# STM32L0x0 register map
File version: 1.3
CPU: CM0+ r0p0, little endian, MPU, no FPU, 2 interrupt priority bits
Registers are 32-bit, read-write, reset 0x0 unless marked. A register's access mark holds for its fields unless they carry their own. Offsets are from the block's base; [hi:lo] are bit positions; {n}, {i} and the like mark numbered series; 'fields as' and 'values as' point back to an identical list.

## IWDG — Independent watchdog
Base 0x40003000
0x00 KR 16-bit wo — Key register
  [15:0] KEY — Key value (write only, read 0x0000)
    0x5555=Unlock (Enable access to PR, RLR and WINR registers); 0xAAAA=Feed watchdog with RLR register value; 0xCCCC=Start the watchdog
0x04 PR 16-bit — Prescaler register
  [2:0] PR — Prescaler divider
    0=DivideBy4 (Divider /4); 1=DivideBy8 (Divider /8); 2=DivideBy16 (Divider /16); 3=DivideBy32 (Divider /32); 4=DivideBy64 (Divider /64); 5=DivideBy128 (Divider /128); other=DivideBy256 (Divider /256)
0x08 RLR 16-bit reset 0xFFF — Reload register
  [11:0] RL — Watchdog counter reload value
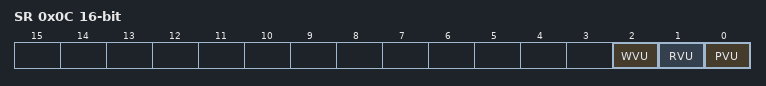
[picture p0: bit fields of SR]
0x0C SR 16-bit ro — Status register
  [2] WVU — Watchdog counter window value update
  [1] RVU — Watchdog counter reload value update
  [0] PVU — Watchdog prescaler value update
0x10 WINR 16-bit reset 0xFFF — Window register
  [11:0] WIN — Watchdog counter window value

## WWDG — System window watchdog
Base 0x40002C00
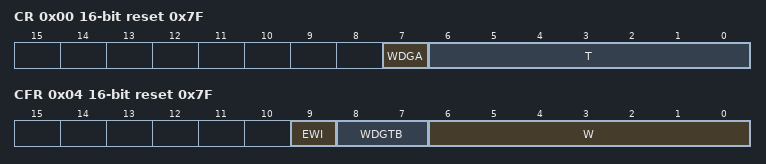
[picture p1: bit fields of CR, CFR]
0x00 CR 16-bit reset 0x7F — Control register
  [7] WDGA — Activation bit
    0=Disabled (Watchdog disabled); 1=Enabled (Watchdog enabled)
  [6:0] T — 7-bit counter (MSB to LSB)
0x04 CFR 16-bit reset 0x7F — Configuration register
  [9] EWI — Early wakeup interrupt
    on write: 1=Enable (interrupt occurs whenever the counter reaches the value 0x40)
  [8:7] WDGTB — Timer base
    0=Div1 (Counter clock (PCLK1 div 4096) div 1); 1=Div2 (Counter clock (PCLK1 div 4096) div 2); 2=Div4 (Counter clock (PCLK1 div 4096) div 4); 3=Div8 (Counter clock (PCLK1 div 4096) div 8)
  [6:0] W — 7-bit window value
0x08 SR 16-bit — Status register
  [0] EWIF write-0-clears — Early wakeup interrupt flag
    on read: 0=Finished (The EWI Interrupt Service Routine has been serviced); 1=Pending (The EWI Interrupt Service Routine has been triggered) | on write: 0=Finished (The EWI Interrupt Service Routine has been serviced)

## FW — Firewall
Base 0x40011C00
0x00 CSSA — Code segment start address
  [23:8] ADD — code segment start address
0x04 CSL — Code segment length
  [21:8] LENG — code segment length
0x08 NVDSSA — Non-volatile data segment start address
  [23:8] ADD
0x0C NVDSL — Non-volatile data segment length
  [21:8] LENG
0x10 VDSSA — Volatile data segment start address
  [15:6] ADD
0x14 VDSL — Volatile data segment length
  [15:6] LENG — Non-volatile data segment length
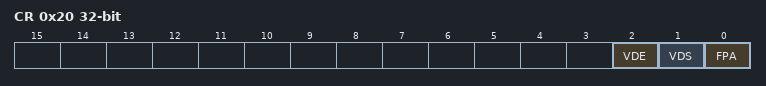
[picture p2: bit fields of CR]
0x20 CR — Configuration register
  [2] VDE — Volatile data execution
    on read: 0=NotExecutable (Volatile data segment cannot be executed if VDS = 0); 1=Executable (Volatile data segment is declared executable whatever VDS bit value) | on write: 0=Resets volatile data execution bit
  [1] VDS — Volatile data shared
    on read: 0=NotShared (Volatile data segment is not shared and cannot be hit by a non protected executable code when the Firewall is closed); 1=Shared (Volatile data segment is shared with non protected application code) | on write: 0=Resets volatile data shared bit
  [0] FPA — Firewall pre alarm
    on write: 0=PreArmReset (Any code executed outside the protected segment when the Firewall is opened will generate a system reset); 1=PreArmSet (Any code executed outside the protected segment will close the Firewall)

## EXTI — External interrupt/event controller
Base 0x40010400
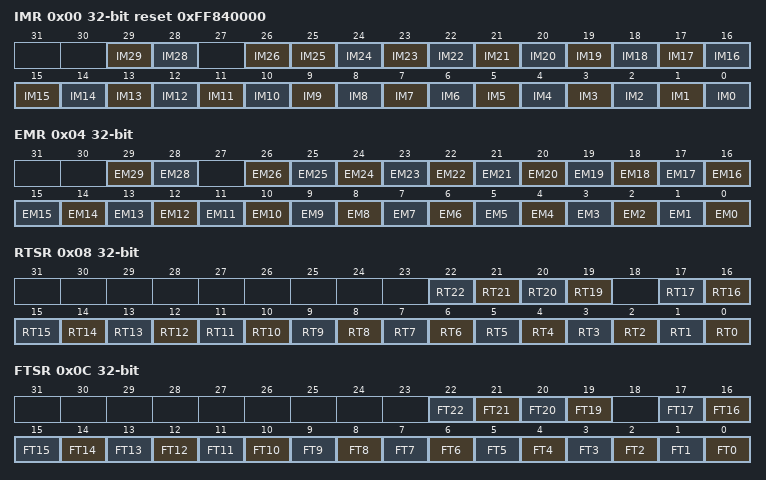
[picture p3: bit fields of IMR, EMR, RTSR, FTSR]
0x00 IMR reset 0xFF840000 — Interrupt mask register (EXTI_IMR)
  [all] fields
    0=Masked (Interrupt request line is masked); 1=Unmasked (Interrupt request line is unmasked)
  [29] IM29 — Interrupt Mask on line 27
  [28] IM28 — Interrupt Mask on line 27
  [26] IM26 — Interrupt Mask on line 27
  [n] IM{n} (n=0..25) — Interrupt Mask on line {n}
0x04 EMR — Event mask register (EXTI_EMR)
  [all] fields
    0=Masked (Event request line is masked); 1=Unmasked (Event request line is unmasked)
  [29] EM29 — Event Mask on line 29
  [28] EM28 — Event Mask on line 28
  [n] EM{n} (n=0..26) — Event Mask on line {n}
0x08 RTSR — Rising Trigger selection register (EXTI_RTSR)
  [all] fields
    0=Disabled (Rising edge trigger is disabled); 1=Enabled (Rising edge trigger is enabled)
  [n] RT{n} (n=19..22) — Rising trigger event configuration of line {n}
  [n] RT{n} (n=0..17) — Rising trigger event configuration of line {n}
0x0C FTSR — Falling Trigger selection register (EXTI_FTSR)
  [all] fields
    0=Disabled (Falling edge trigger is disabled); 1=Enabled (Falling edge trigger is enabled)
  [n] FT{n} (n=19..22) — Falling trigger event configuration of line {n}
  [n] FT{n} (n=0..17) — Falling trigger event configuration of line {n}
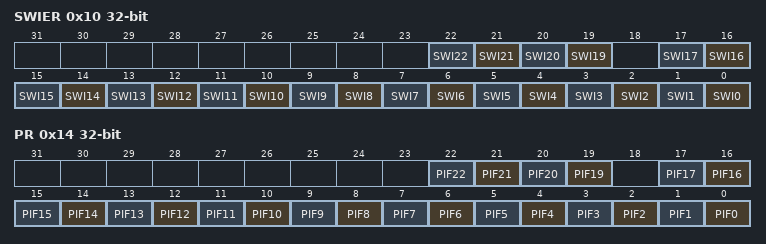
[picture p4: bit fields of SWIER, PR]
0x10 SWIER — Software interrupt event register (EXTI_SWIER)
  [all] fields
    on write: 1=Pend (Generates an interrupt request)
  [n] SWI{n} (n=19..22) — Software Interrupt on line {n}
  [n] SWI{n} (n=0..17) — Software Interrupt on line {n}
0x14 PR — Pending register (EXTI_PR)
  [all] fields
    on read: 0=NotPending (No trigger request occurred); 1=Pending (Selected trigger request occurred) | on write: 1=Clears pending bit
  [n] PIF{n} write-1-clears (n=19..22) — Pending bit {n}
  [n] PIF{n} write-1-clears (n=0..17) — Pending bit {n}

## DBG — Debug support
Base 0x40015800
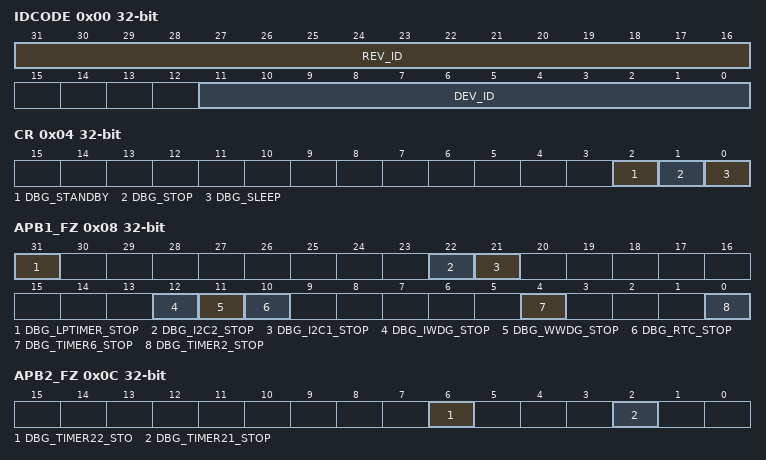
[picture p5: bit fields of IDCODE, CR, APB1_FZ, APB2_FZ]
0x00 IDCODE ro — MCU Device ID Code Register
  [31:16] REV_ID — Revision Identifier
  [11:0] DEV_ID — Device Identifier
0x04 CR — Debug MCU Configuration Register
  [2] DBG_STANDBY — Debug Standby Mode
    0=Disabled (Debug Standby Mode Disabled); 1=Enabled (Debug Standby Mode Enabled)
  [1] DBG_STOP — Debug Stop Mode
    0=Disabled (Debug Stop Mode Disabled); 1=Enabled (Debug Stop Mode Enabled)
  [0] DBG_SLEEP — Debug Sleep Mode
    0=Disabled (Debug Sleep Mode Disabled); 1=Enabled (Debug Sleep Mode Enabled)
0x08 APB1_FZ — APB Low Freeze Register
  [31] DBG_LPTIMER_STOP — LPTIM1 counter stopped when core is halted
    0=Continue (LPTIM1 counter clock is fed even if the core is halted); 1=Stop (LPTIM1 counter clock is stopped when the core is halted)
  [22] DBG_I2C2_STOP — I2C2 SMBUS timeout mode stopped when core is halted
    0=NormalMode (Same behavior as in normal mode); 1=SMBusTimeoutFrozen (I2C3 SMBUS timeout is frozen)
  [21] DBG_I2C1_STOP — I2C1 SMBUS timeout mode stopped when core is halted
    values as DBG_I2C2_STOP
  [12] DBG_IWDG_STOP — Debug Independent Wachdog stopped when Core is halted
    0=Continue (The independent watchdog counter clock continues even if the core is halted); 1=Stop (The independent watchdog counter clock is stopped when the core is halted)
  [11] DBG_WWDG_STOP — Debug Window Wachdog stopped when Core is halted
    0=Continue (The window watchdog counter clock continues even if the core is halted); 1=Stop (The window watchdog counter clock is stopped when the core is halted)
  [10] DBG_RTC_STOP — Debug RTC stopped when Core is halted
    0=Continue (The clock of the RTC counter is fed even if the core is halted); 1=Stop (The clock of the RTC counter is stopped when the core is halted)
  [4] DBG_TIMER6_STOP — Debug Timer 6 stopped when Core is halted
    0=Continue (The counter clock of TIMx is fed even if the core is halted); 1=Stop (The counter clock of TIMx is stopped when the core is halted)
  [0] DBG_TIMER2_STOP — Debug Timer 2 stopped when Core is halted
    values as DBG_TIMER6_STOP
0x0C APB2_FZ — APB High Freeze Register
  [6] DBG_TIMER22_STO — Debug Timer 22 stopped when Core is halted
  [2] DBG_TIMER21_STOP — Debug Timer 21 stopped when Core is halted
    values as APB1_FZ.DBG_TIMER6_STOP

## NVIC — Nested Vectored Interrupt Controller
Base 0xE000E100
0x00 ISER — Interrupt Set Enable Register
  [31:0] SETENA
0x80 ICER — Interrupt Clear Enable Register
  [31:0] CLRENA
0x100 ISPR — Interrupt Set-Pending Register
  [31:0] SETPEND
0x180 ICPR — Interrupt Clear-Pending Register
  [31:0] CLRPEND
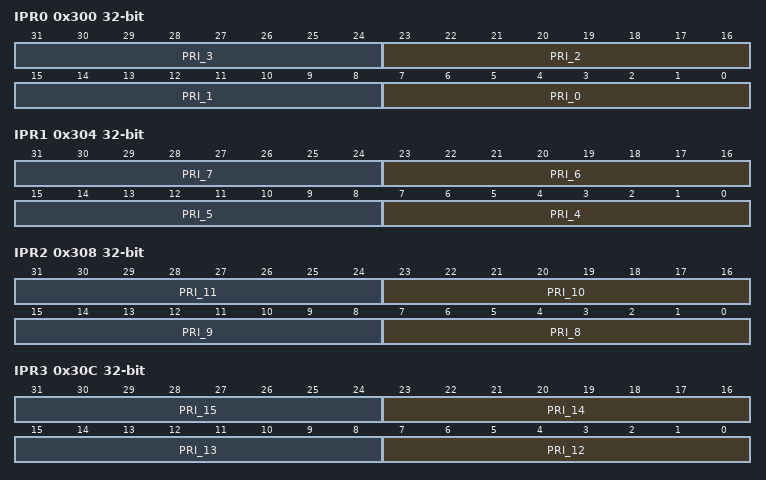
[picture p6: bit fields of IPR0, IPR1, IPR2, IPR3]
0x300 IPR0 — Interrupt Priority Register 0
  [8n+7:8n] PRI_{n} (n=0..3) — priority for interrupt {n}
0x304 IPR1 — Interrupt Priority Register 1
  [8n-25:8n-32] PRI_{n} (n=4..7) — priority for interrupt n
0x308 IPR2 — Interrupt Priority Register 2
  [8n-57:8n-64] PRI_{n} (n=8..11) — priority for interrupt n
0x30C IPR3 — Interrupt Priority Register 3
  [8n-89:8n-96] PRI_{n} (n=12..15) — priority for interrupt n
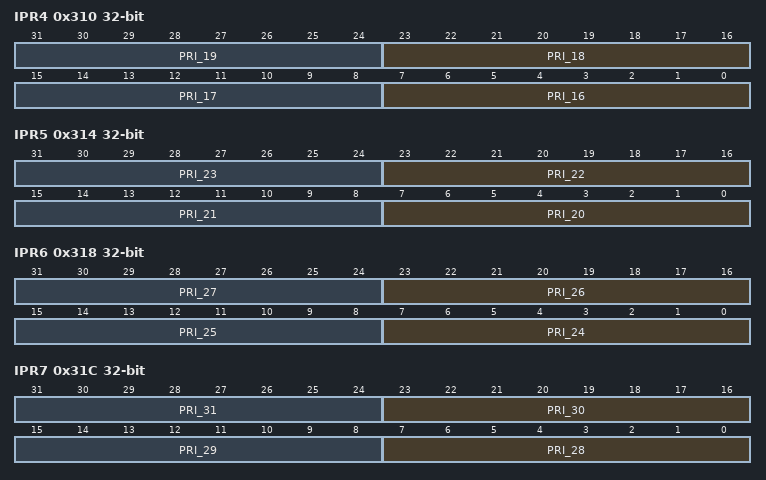
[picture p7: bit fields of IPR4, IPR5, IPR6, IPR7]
0x310 IPR4 — Interrupt Priority Register 4
  [8n-121:8n-128] PRI_{n} (n=16..19) — priority for interrupt n
0x314 IPR5 — Interrupt Priority Register 5
  [8n-153:8n-160] PRI_{n} (n=20..23) — priority for interrupt n
0x318 IPR6 — Interrupt Priority Register 6
  [8n-185:8n-192] PRI_{n} (n=24..27) — priority for interrupt n
0x31C IPR7 — Interrupt Priority Register 7
  [8n-217:8n-224] PRI_{n} (n=28..31) — priority for interrupt n
